# G32F002 register map
File version: 1.0
CPU: CM0PLUS r0p1, little endian, no MPU, no FPU, 4 interrupt priority bits
Registers are 32-bit, read-write, reset 0x0 unless marked. A register's access mark holds for its fields unless they carry their own. Offsets are from the block's base; [hi:lo] are bit positions; {n}, {i} and the like mark numbered series.

## EINT — External interrupt/event controller
Base 0x40009000
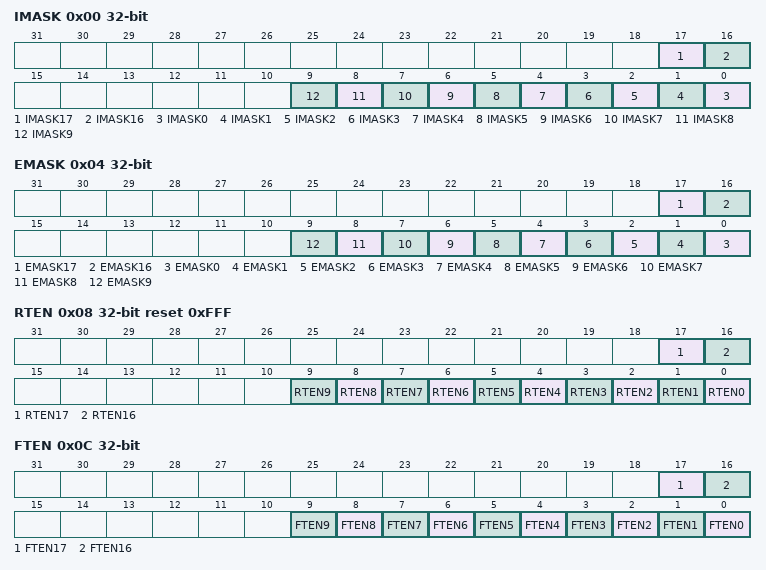
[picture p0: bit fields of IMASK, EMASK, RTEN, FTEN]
0x00 IMASK
  [17] IMASK17 — Interrupt request mask on line 17
  [16] IMASK16 — Interrupt request mask on line 16
  [n] IMASK{n} (n=0..9) — Interrupt request mask on line {n}
0x04 EMASK
  [17] EMASK17 — Event request mask on line 17
  [16] EMASK16 — Event request mask on line 16
  [n] EMASK{n} (n=0..9) — Event request mask on line {n}
0x08 RTEN reset 0xFFF
  [17] RTEN17 — Rising trigger event enable and interrupt of line 17
  [16] RTEN16 — Rising trigger event enable and interrupt of line 16
  [n] RTEN{n} (n=0..9) — Rising trigger event enable and interrupt of line {n}
0x0C FTEN
  [17] FTEN17 — Falling trigger event enable and interrupt of line 17
  [16] FTEN16 — Falling trigger event enable and interrupt of line 16
  [n] FTEN{n} (n=0..9) — Falling trigger event enable and interrupt of line {n}
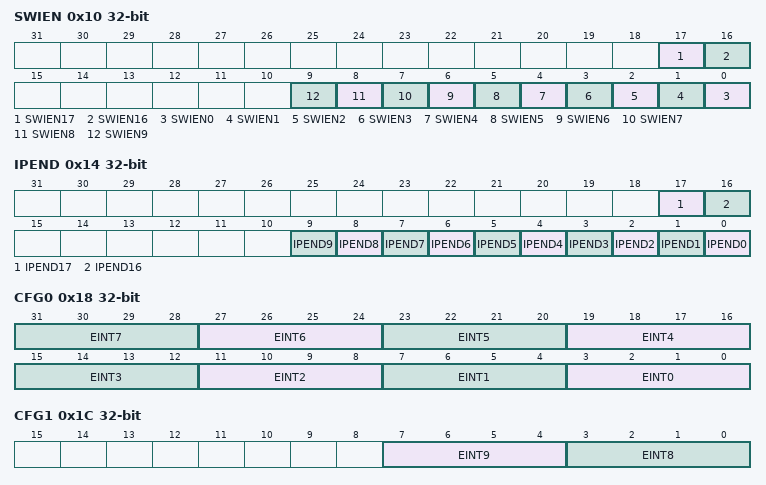
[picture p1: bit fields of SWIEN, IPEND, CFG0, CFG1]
0x10 SWIEN
  [17] SWIEN17 — Software interrupt event on line 17
  [16] SWIEN16 — Software interrupt event on line 16
  [n] SWIEN{n} (n=0..9) — Software interrupt event on line {n}
0x14 IPEND
  [17] IPEND17 — Interrupt pending occur of line 17
  [16] IPEND16 — Interrupt pending occur of line 16
  [n] IPEND{n} (n=0..9) — Interrupt pending occur of line {n}
0x18 CFG0
  [4n+3:4n] EINT{n} (n=0..7) — /
0x1C CFG1
  [7:4] EINT9 — /
  [3:0] EINT8 — /

## BTMR — Base timer
Base 0x40001000
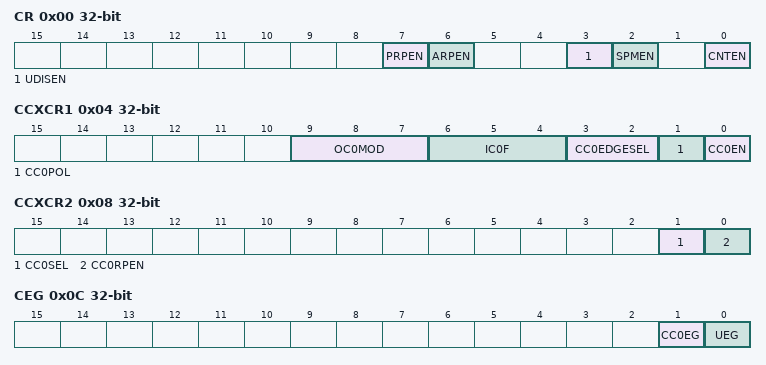
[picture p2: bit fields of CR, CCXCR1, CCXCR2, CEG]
0x00 CR — control register 1
  [7] PRPEN — PSC preload enable
  [6] ARPEN — Auto-reload Preload Enable
  [3] UDISEN — Update Disable
  [2] SPMEN — Single Pulse Mode Enable
  [0] CNTEN — BTMR enable
0x04 CCXCR1 — channel control register 1
  [9:7] OC0MOD — Output Compare Channel0 Mode Configure
  [6:4] IC0F — Input filter coefficients (based on timer clock)
  [3:2] CC0EDGESEL — When in input mode: capture the active edge
  [1] CC0POL — Capture/Compare Channel1 Output Polarity Configure
  [0] CC0EN — Capture/compare enable
0x08 CCXCR2 — channel control register 2
  [1] CC0SEL — Channel 0 Input/Output Selection
  [0] CC0RPEN — CCR0 register auto-reload buffer enable
0x0C CEG wo — event generation register
  [1] CC0EG — Capture/compare 0 generation
  [0] UEG — Update generation
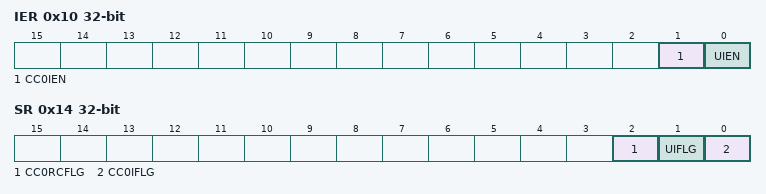
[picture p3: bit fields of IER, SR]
0x10 IER — interrupt enable register
  [1] CC0IEN — Capture/compare 0 interrupt enable
  [0] UIEN — Update interrupt enable
0x14 SR — status register
  [2] CC0RCFLG — Captuer/Compare Channel0 Repetition Capture Flag
  [1] UIFLG — Update interrupt flag
  [0] CC0IFLG — Capture/compare 0 interrupt flag
0x18 CNT — counter
  [15:0] CNT — Counter Value
0x1C PSC — prescaler
  [15:0] PSC — Prescaler value
0x20 AUTORLD reset 0xFFFF — auto-reload register
  [15:0] AUTORLD — Auto Reload Value
0x24 CC0 — capture/compare register 0
  [15:0] CC0 — Capture/Compare 0 value

## LPTMR — Low-power timer
Base 0x4000A000
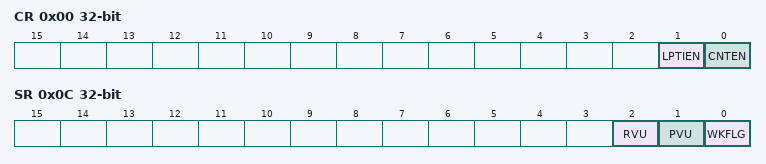
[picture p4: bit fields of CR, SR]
0x00 CR — Control register
  [1] LPTIEN — Interrupt enable
  [0] CNTEN — Module enablement
0x04 PSC — Prescaler register
  [15:0] PSC — Prescaler divider
0x08 WKVAL reset 0xFFFF — Reload register
  [15:0] WKVAL — Awakening Value
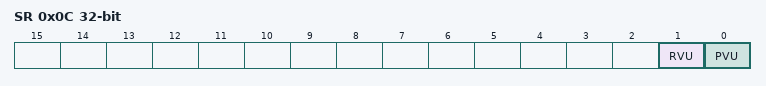
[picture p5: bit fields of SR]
0x0C SR ro — Status register
  [2] RVU — Reload value update indication, automatically reset by hardware after update.
  [1] PVU — PS value update indicator, hardware automatically resets after update.
  [0] WKFLG — Status Register, read SR register clear.
0x10 CNT ro — Counter register
  [15:0] CNT — Counter Value

## IWDT — Independent watchdog
Base 0x40008000
0x00 KEY wo
  [15:0] KEY — Key value (write only, read 0000h)
0x04 PSC reset 0x7 — Prescaler register
  [2:0] PSC — Prescaler divider
0x08 RLR reset 0xFFF — Reload register
  [11:0] RLR — Watchdog counter reload value
0x0C SR ro — Status register
  [1] RVU — Watchdog prescaler value update
  [0] PVU — Watchdog counter reload value update
